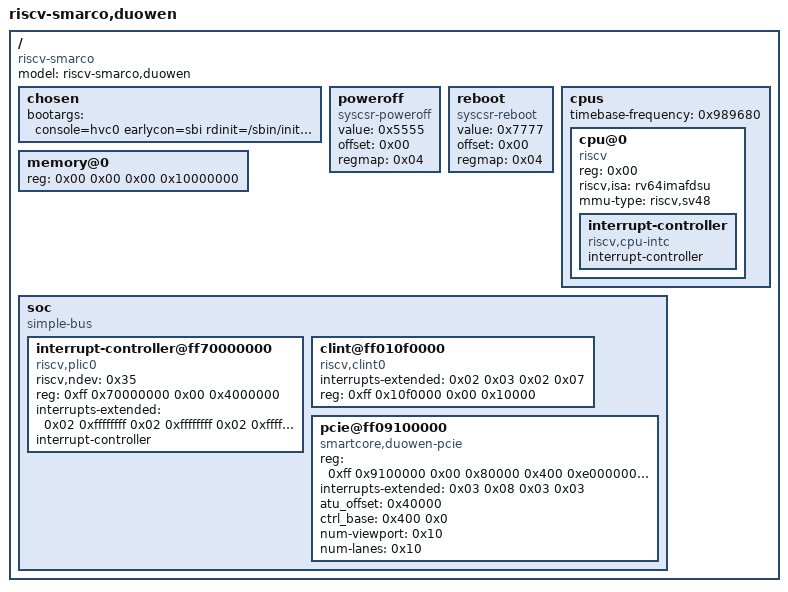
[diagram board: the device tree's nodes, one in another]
/dts-v1/;

/ {
	#address-cells = < 0x02 >;
	#size-cells = < 0x02 >;
	compatible = "riscv-smarco";
	model = "riscv-smarco,duowen";

	chosen {
		bootargs = "console=hvc0 earlycon=sbi rdinit=/sbin/init nvme_core.default_ps_max_latency_us=250";
	};

	poweroff {
		value = < 0x5555 >;
		offset = < 0x00 >;
		regmap = < 0x04 >;
		compatible = "syscsr-poweroff";
	};

	reboot {
		value = < 0x7777 >;
		offset = < 0x00 >;
		regmap = < 0x04 >;
		compatible = "syscsr-reboot";
	};

	cpus {
		#address-cells = < 0x01 >;
		#size-cells = < 0x00 >;
		timebase-frequency = < 0x989680 >;

		cpu@0 {
			phandle = < 0x01 >;
			device_type = "cpu";
			reg = < 0x00 >;
			status = "okay";
			compatible = "riscv";
			riscv,isa = "rv64imafdsu";
			mmu-type = "riscv,sv48";

			interrupt-controller {
				#interrupt-cells = < 0x01 >;
				interrupt-controller;
				compatible = "riscv,cpu-intc";
				phandle = < 0x02 >;
			};
		};
	};

	memory@0 {
		device_type = "memory";
		reg = < 0x00 0x00 0x00 0x10000000 >;
	};

	soc {
		#address-cells = < 0x02 >;
		#size-cells = < 0x02 >;
		compatible = "simple-bus";
		ranges;

		interrupt-controller@ff70000000 {
			riscv,ndev = < 0x35 >;
			reg = < 0xff 0x70000000 0x00 0x4000000 >;
			interrupts-extended = < 0x02 0xffffffff 0x02 0xffffffff 0x02 0xffffffff 0x02 0xffffffff 0x02 0xffffffff 0x02 0xffffffff 0x02 0xffffffff 0x02 0xffffffff 0x02 0xffffffff 0x02 0xffffffff 0x02 0xffffffff 0x02 0xffffffff 0x02 0xffffffff 0x02 0xffffffff 0x02 0xffffffff 0x02 0xffffffff 0x02 0xffffffff 0x02 0x09 >;
			interrupt-controller;
			compatible = "riscv,plic0";
			#interrupt-cells = < 0x01 >;
			#address-cells = < 0x00 >;
			phandle = < 0x03 >;
		};

		clint@ff010f0000 {
			interrupts-extended = < 0x02 0x03 0x02 0x07 >;
			reg = < 0xff 0x10f0000 0x00 0x10000 >;
			compatible = "riscv,clint0";
		};

		pcie@ff09100000 {
			compatible = "smartcore,duowen-pcie";
			reg = < 0xff 0x9100000 0x00 0x80000 0x400 0xe0000000 0x00 0x2000000 >;
			reg-names = "dbi\0config";
			#address-cells = < 0x03 >;
			#size-cells = < 0x02 >;
			device_type = "pci";
			ranges = < 0x83000000 0x00 0x00 0x400 0x00 0x00 0xe0000000 0x81000000 0x01 0x00 0x401 0x00 0x00 0x100000 >;
			interrupts-extended = < 0x03 0x08 0x03 0x03 >;
			atu_offset = < 0x40000 >;
			ctrl_base = < 0x400 0x0 >;
			num-viewport = < 0x10 >;
			num-lanes = < 0x10 >;
		};
	};
};
